# ioat91sam3s4 register map
Registers are 32-bit, access not given, no defined reset value unless marked. A register's access mark holds for its fields unless they carry their own. Addresses are absolute; registers are grouped by the start of their names; [hi:lo] are bit positions; 'fields as' and 'values as' point back to an identical list.

## USART0
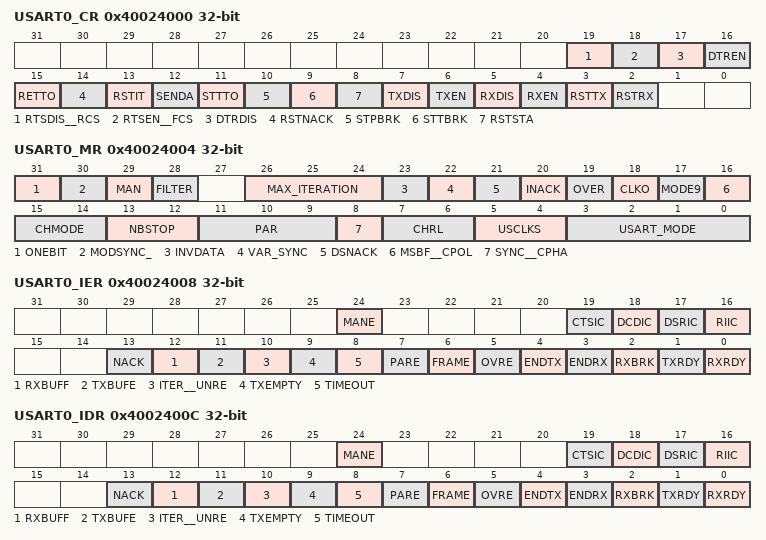
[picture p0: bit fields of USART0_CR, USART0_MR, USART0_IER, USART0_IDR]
0x40024000 USART0_CR
  [19] RTSDIS__RCS, [18] RTSEN__FCS, [17] DTRDIS, [16] DTREN, [15] RETTO, [14] RSTNACK, [13] RSTIT, [12] SENDA, [11] STTTO, [10] STPBRK, [9] STTBRK, [8] RSTSTA, [7] TXDIS, [6] TXEN, [5] RXDIS, [4] RXEN, [3] RSTTX, [2] RSTRX
0x40024004 USART0_MR
  [31] ONEBIT, [30] MODSYNC_, [29] MAN, [28] FILTER, [26:24] MAX_ITERATION, [23] INVDATA, [22] VAR_SYNC, [21] DSNACK, [20] INACK, [19] OVER, [18] CLKO, [17] MODE9, [16] MSBF__CPOL, [15:14] CHMODE, [13:12] NBSTOP, [11:9] PAR, [8] SYNC__CPHA, [7:6] CHRL, [5:4] USCLKS, [3:0] USART_MODE
0x40024008 USART0_IER
  [24] MANE, [19] CTSIC, [18] DCDIC, [17] DSRIC, [16] RIIC, [13] NACK, [12] RXBUFF, [11] TXBUFE, [10] ITER__UNRE, [9] TXEMPTY, [8] TIMEOUT, [7] PARE, [6] FRAME, [5] OVRE, [4] ENDTX, [3] ENDRX, [2] RXBRK, [1] TXRDY, [0] RXRDY
0x4002400C USART0_IDR
  fields as USART0_IER
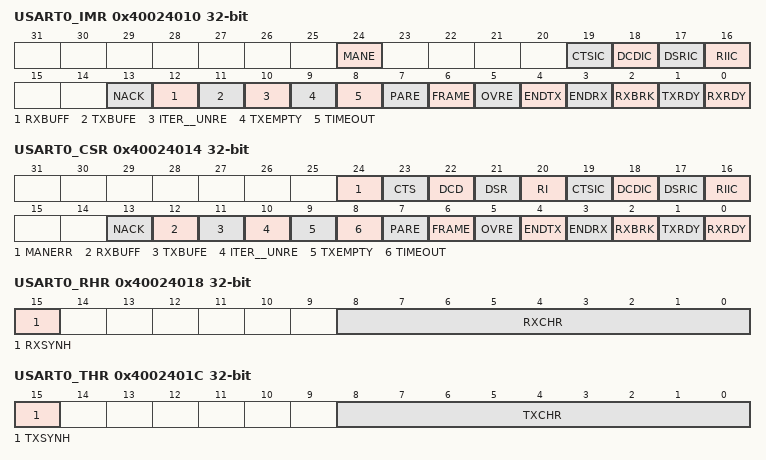
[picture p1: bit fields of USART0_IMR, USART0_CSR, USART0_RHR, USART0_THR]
0x40024010 USART0_IMR
  fields as USART0_IER
0x40024014 USART0_CSR
  [24] MANERR, [23] CTS, [22] DCD, [21] DSR, [20] RI, [19] CTSIC, [18] DCDIC, [17] DSRIC, [16] RIIC, [13] NACK, [12] RXBUFF, [11] TXBUFE, [10] ITER__UNRE, [9] TXEMPTY, [8] TIMEOUT, [7] PARE, [6] FRAME, [5] OVRE, [4] ENDTX, [3] ENDRX, [2] RXBRK, [1] TXRDY, [0] RXRDY
0x40024018 USART0_RHR
  [15] RXSYNH, [8:0] RXCHR
0x4002401C USART0_THR
  [15] TXSYNH, [8:0] TXCHR
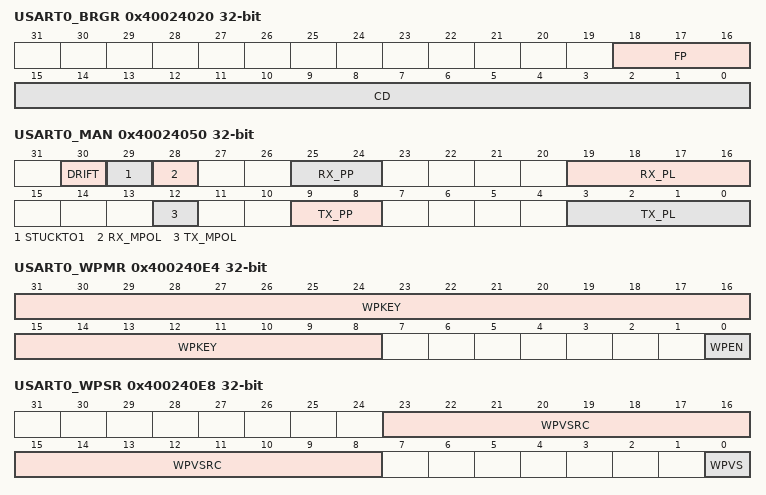
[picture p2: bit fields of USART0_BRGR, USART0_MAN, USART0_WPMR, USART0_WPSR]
0x40024020 USART0_BRGR
  [18:16] FP, [15:0] CD
0x40024024 USART0_RTOR
  [15:0] TO
0x40024028 USART0_TTGR
  [7:0] TG
0x40024040 USART0_FIDI
  [10:0] FI_DI_RATIO
0x40024044 USART0_NER
  [7:0] NB_ERRORS
0x4002404C USART0_IF
  [7:0] IRDA_FILTER
0x40024050 USART0_MAN
  [30] DRIFT, [29] STUCKTO1, [28] RX_MPOL, [25:24] RX_PP, [19:16] RX_PL, [12] TX_MPOL, [9:8] TX_PP, [3:0] TX_PL
0x400240E4 USART0_WPMR
  [31:8] WPKEY, [0] WPEN
0x400240E8 USART0_WPSR
  [23:8] WPVSRC, [0] WPVS
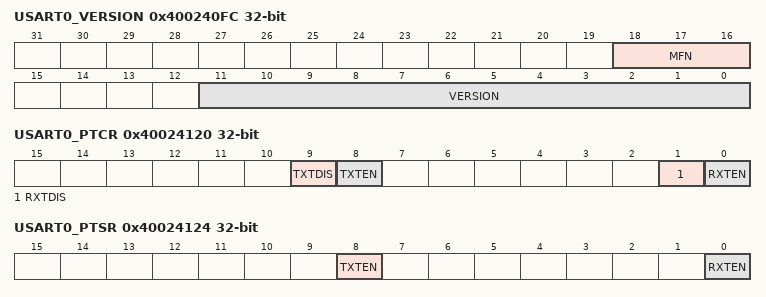
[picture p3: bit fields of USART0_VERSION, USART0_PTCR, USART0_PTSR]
0x400240FC USART0_VERSION
  [18:16] MFN, [11:0] VERSION
0x40024100 USART0_RPR
  [31:0] RXPTR
0x40024104 USART0_RCR
  [15:0] RXCTR
0x40024108 USART0_TPR
  [31:0] TXPTR
0x4002410C USART0_TCR
  [15:0] TXCTR
0x40024110 USART0_RNPR
  [31:0] RXNPTR
0x40024114 USART0_RNCR
  [15:0] RXNCTR
0x40024118 USART0_TNPR
  [31:0] TXNPTR
0x4002411C USART0_TNCR
  [15:0] TXNCTR
0x40024120 USART0_PTCR
  [9] TXTDIS, [8] TXTEN, [1] RXTDIS, [0] RXTEN
0x40024124 USART0_PTSR
  [8] TXTEN, [0] RXTEN

## USART1
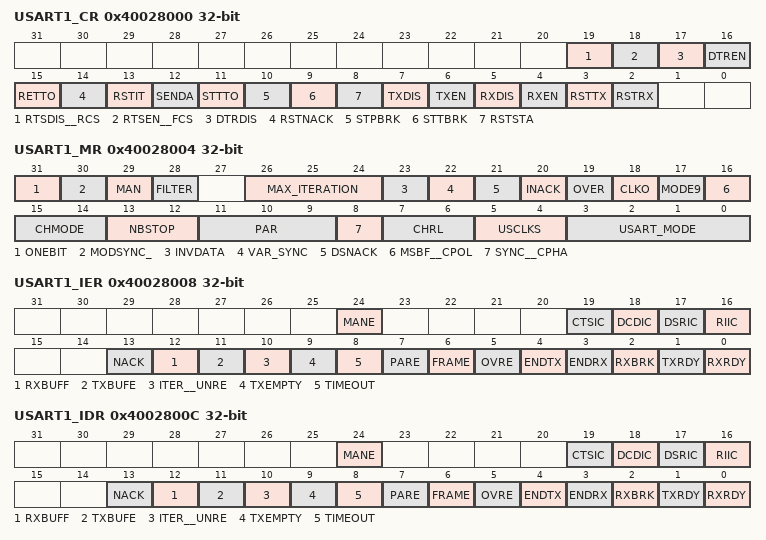
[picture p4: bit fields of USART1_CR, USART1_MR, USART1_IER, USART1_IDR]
0x40028000 USART1_CR
  [19] RTSDIS__RCS, [18] RTSEN__FCS, [17] DTRDIS, [16] DTREN, [15] RETTO, [14] RSTNACK, [13] RSTIT, [12] SENDA, [11] STTTO, [10] STPBRK, [9] STTBRK, [8] RSTSTA, [7] TXDIS, [6] TXEN, [5] RXDIS, [4] RXEN, [3] RSTTX, [2] RSTRX
0x40028004 USART1_MR
  [31] ONEBIT, [30] MODSYNC_, [29] MAN, [28] FILTER, [26:24] MAX_ITERATION, [23] INVDATA, [22] VAR_SYNC, [21] DSNACK, [20] INACK, [19] OVER, [18] CLKO, [17] MODE9, [16] MSBF__CPOL, [15:14] CHMODE, [13:12] NBSTOP, [11:9] PAR, [8] SYNC__CPHA, [7:6] CHRL, [5:4] USCLKS, [3:0] USART_MODE
0x40028008 USART1_IER
  [24] MANE, [19] CTSIC, [18] DCDIC, [17] DSRIC, [16] RIIC, [13] NACK, [12] RXBUFF, [11] TXBUFE, [10] ITER__UNRE, [9] TXEMPTY, [8] TIMEOUT, [7] PARE, [6] FRAME, [5] OVRE, [4] ENDTX, [3] ENDRX, [2] RXBRK, [1] TXRDY, [0] RXRDY
0x4002800C USART1_IDR
  fields as USART1_IER
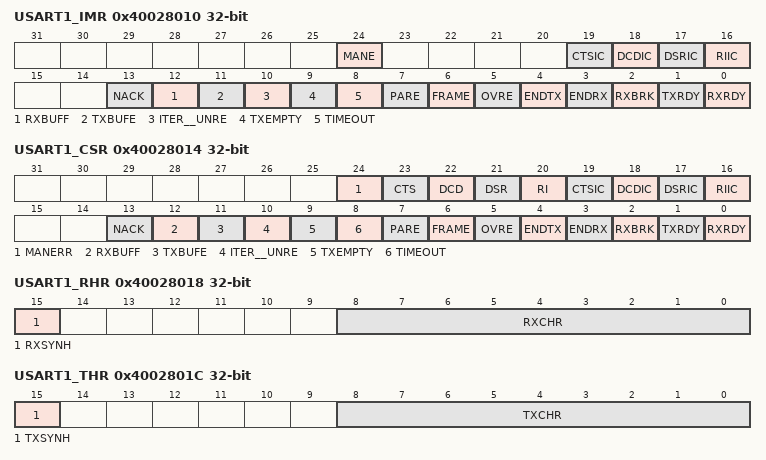
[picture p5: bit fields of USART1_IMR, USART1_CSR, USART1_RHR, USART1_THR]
0x40028010 USART1_IMR
  fields as USART1_IER
0x40028014 USART1_CSR
  [24] MANERR, [23] CTS, [22] DCD, [21] DSR, [20] RI, [19] CTSIC, [18] DCDIC, [17] DSRIC, [16] RIIC, [13] NACK, [12] RXBUFF, [11] TXBUFE, [10] ITER__UNRE, [9] TXEMPTY, [8] TIMEOUT, [7] PARE, [6] FRAME, [5] OVRE, [4] ENDTX, [3] ENDRX, [2] RXBRK, [1] TXRDY, [0] RXRDY
0x40028018 USART1_RHR
  [15] RXSYNH, [8:0] RXCHR
0x4002801C USART1_THR
  [15] TXSYNH, [8:0] TXCHR
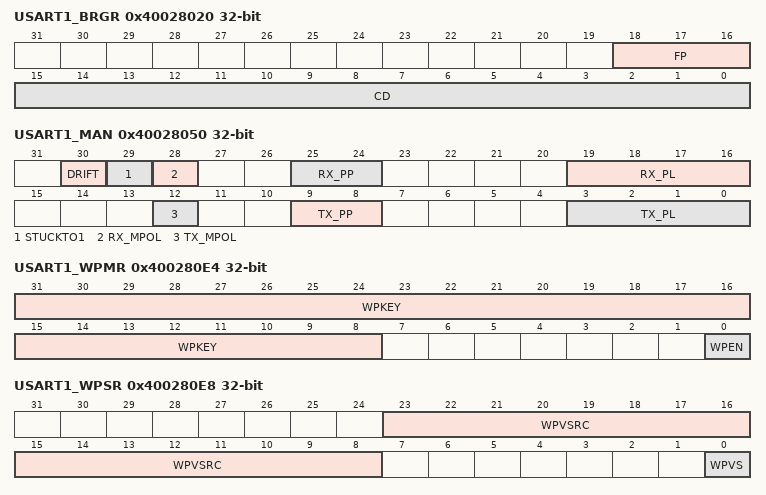
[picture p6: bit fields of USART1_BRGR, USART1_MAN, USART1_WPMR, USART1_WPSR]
0x40028020 USART1_BRGR
  [18:16] FP, [15:0] CD
0x40028024 USART1_RTOR
  [15:0] TO
0x40028028 USART1_TTGR
  [7:0] TG
0x40028040 USART1_FIDI
  [10:0] FI_DI_RATIO
0x40028044 USART1_NER
  [7:0] NB_ERRORS
0x4002804C USART1_IF
  [7:0] IRDA_FILTER
0x40028050 USART1_MAN
  [30] DRIFT, [29] STUCKTO1, [28] RX_MPOL, [25:24] RX_PP, [19:16] RX_PL, [12] TX_MPOL, [9:8] TX_PP, [3:0] TX_PL
0x400280E4 USART1_WPMR
  [31:8] WPKEY, [0] WPEN
0x400280E8 USART1_WPSR
  [23:8] WPVSRC, [0] WPVS
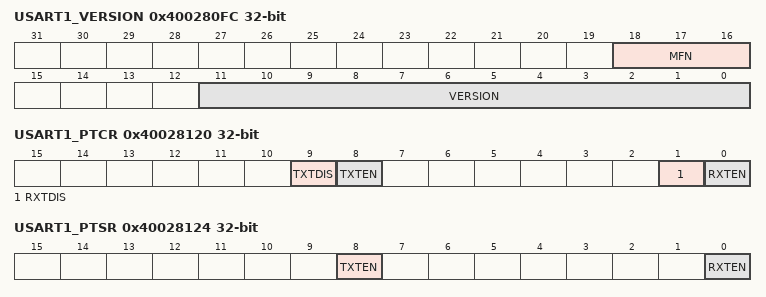
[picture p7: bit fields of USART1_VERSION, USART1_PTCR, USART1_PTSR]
0x400280FC USART1_VERSION
  [18:16] MFN, [11:0] VERSION
0x40028100 USART1_RPR
  [31:0] RXPTR
0x40028104 USART1_RCR
  [15:0] RXCTR
0x40028108 USART1_TPR
  [31:0] TXPTR
0x4002810C USART1_TCR
  [15:0] TXCTR
0x40028110 USART1_RNPR
  [31:0] RXNPTR
0x40028114 USART1_RNCR
  [15:0] RXNCTR
0x40028118 USART1_TNPR
  [31:0] TXNPTR
0x4002811C USART1_TNCR
  [15:0] TXNCTR
0x40028120 USART1_PTCR
  [9] TXTDIS, [8] TXTEN, [1] RXTDIS, [0] RXTEN
0x40028124 USART1_PTSR
  [8] TXTEN, [0] RXTEN
